# CC3220SF register map
Vendor: Texas Instruments; Series: Wireless Connectivity MCU; File version: 1
CPU: CM4 r1p0, little endian, no MPU, no FPU, 8 interrupt priority bits
Registers are 32-bit, read-write, reset 0x0 unless marked. A register's access mark holds for its fields unless they carry their own. Offsets are from the block's base; [hi:lo] are bit positions; {n}, {i} and the like mark numbered series.

## HIB3P3
Base 0x4402F800
0x00 MEM_HIB_REQ
  [8:2] NU1
0x04 MEM_HIB_RTC_TIMER_ENABLE
0x08 MEM_HIB_RTC_TIMER_RESET
0x0C MEM_HIB_RTC_TIMER_READ
0x10 MEM_HIB_RTC_TIMER_LSW
0x14 MEM_HIB_RTC_TIMER_MSW
  [15:0] HIB_RTC_TIMER_MSW — Upper 32b value of the latched RTC-Timer.
0x18 MEM_HIB_RTC_WAKE_EN
0x1C MEM_HIB_RTC_WAKE_LSW_CONF
0x20 MEM_HIB_RTC_WAKE_MSW_CONF
  [15:0] MEM_HIB_RTC_WAKE_MSW_CONF — Configuration for RTC-Timer Wakeup (Upper 16b word)
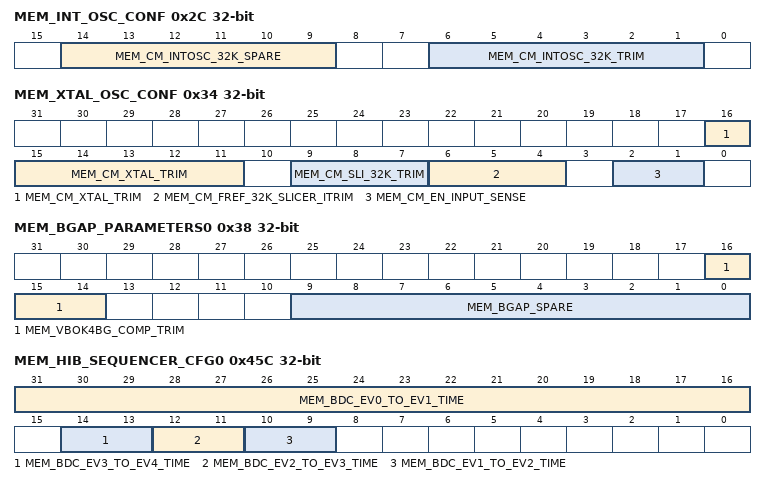
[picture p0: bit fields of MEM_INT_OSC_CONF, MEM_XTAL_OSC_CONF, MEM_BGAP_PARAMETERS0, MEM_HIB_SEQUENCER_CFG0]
0x2C MEM_INT_OSC_CONF
  [14:9] MEM_CM_INTOSC_32K_SPARE, [6:1] MEM_CM_INTOSC_32K_TRIM
0x34 MEM_XTAL_OSC_CONF
  [16:11] MEM_CM_XTAL_TRIM, [9:7] MEM_CM_SLI_32K_TRIM, [6:4] MEM_CM_FREF_32K_SLICER_ITRIM, [2:1] MEM_CM_EN_INPUT_SENSE
0x38 MEM_BGAP_PARAMETERS0
  [16:14] MEM_VBOK4BG_COMP_TRIM, [9:0] MEM_BGAP_SPARE
0x3C MEM_BGAP_PARAMETERS1
  [28:24] MEM_BGAP_ACT_IREF_ITRIM
0x40 MEM_HIB_DETECTION_STATUS
0x44 MEM_HIB_MISC_CONTROLS
  [8:6] MEM_HIB_POK_POR_COMP_TRIM
0x50 MEM_HIB_CONFIG
  [31:24] TOP_MUX_CTRL_SOP_SPIO
0x54 MEM_HIB_RTC_IRQ_ENABLE
0x58 MEM_HIB_RTC_IRQ_LSW_CONF
0x5C MEM_HIB_RTC_IRQ_MSW_CONF
  [15:0] HIB_RTC_IRQ_MSW_CONF — Configuration for MSW of thr RTC-Timestamp at which the interrupt need to be generated
0x400 MEM_HIB_UART_CONF
0x404 MEM_GPIO_WAKE_EN
  [7:0] MEM_GPIO_WAKE_EN — 1 - Enable the GPIO-Autonomous mode wakeup during Hibernate mode ; This is an auto-clear bit, once programmed to 1, it will latched into an internal register which remain asserted until the Hib-wakeup is initiated.
0x408 MEM_GPIO_WAKE_CONF
  [15:0] MEM_GPIO_WAKE_CONF — Configuration to say whether the GPIO wakeup has to happen on Level0 or falling-edge for the given group. 00? Level0 01? Level1 10?- Fall-edge 11?- Rise-edge [1:0] Conf for GPIO0 [3:2] Conf for GPIO1 [5:4] Conf for GPIO2 [7:6] Conf for GPIO3 [9:8] Conf for GPIO4 [11:10] Conf for GPIO5 [13:12] Conf for GPIO6
0x40C MEM_PAD_OEN_RET33_CONF
0x410 MEM_UART_RTS_OEN_RET33_CONF
0x414 MEM_JTAG_CONF
{0x418+4i} MEM_HIB_REG{i} (i=0..3)
0x45C MEM_HIB_SEQUENCER_CFG0
  [31:16] MEM_BDC_EV0_TO_EV1_TIME — Configuration for the number of slow-clks between de-assertion of EN_BG_3P3V to assertion of EN_BG_3P3V
  [14:13] MEM_BDC_EV3_TO_EV4_TIME — Configuration for the number of slow-clks between assertion of EN_COMP_3P3V and assertion of EN_COMP_LATCH_3P3V
  [12:11] MEM_BDC_EV2_TO_EV3_TIME — Configuration for the number of slow-clks between assertion of (EN_CAP_SW_3P3V,EN_COMP_REF) and assertion of (EN_COMP_3P3V)
  [10:9] MEM_BDC_EV1_TO_EV2_TIME — Configuration for the number of slow-clks between assertion of (EN_BG_3P3V) and assertion of (EN_CAP_SW_3P3V, EN_COMP_REF_3P3V)
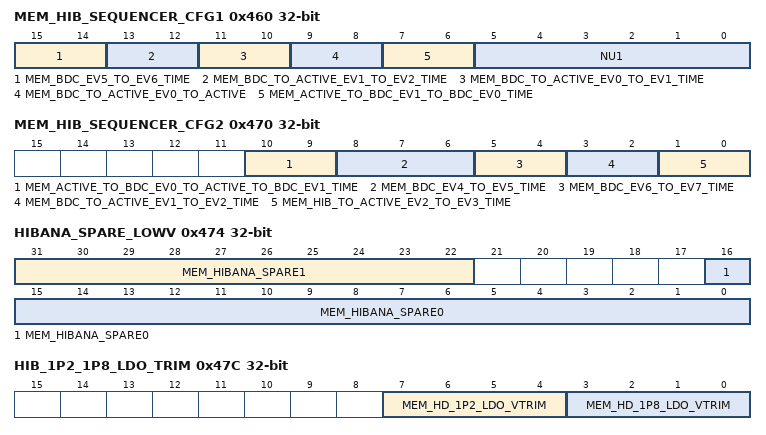
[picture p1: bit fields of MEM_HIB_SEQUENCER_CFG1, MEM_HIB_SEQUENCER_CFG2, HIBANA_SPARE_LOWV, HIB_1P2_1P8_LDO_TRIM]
0x460 MEM_HIB_SEQUENCER_CFG1
  [15:14] MEM_BDC_EV5_TO_EV6_TIME — Configuration for number of slow-clks between de-assertion of EN_COMP_LATCH and assertion of
  [13:12] MEM_BDC_TO_ACTIVE_EV1_TO_EV2_TIME — Configuration for number of slow-clks between assertion of EN_COMP_REF to assertion of EN_COMP during HIB-Exit
  [11:10] MEM_BDC_TO_ACTIVE_EV0_TO_EV1_TIME
  [9:8] MEM_BDC_TO_ACTIVE_EV0_TO_ACTIVE — Configuration in number of slow-clks between assertion of (EN_BGAP_3P3V, EN_CAP_SW_3P3V, EN_ACT_IREF_3P3V, EN_COMP_REF) to assertion of EN_COMP_3P3V
  [7:6] MEM_ACTIVE_TO_BDC_EV1_TO_BDC_EV0_TIME — Configuration in number of slow-clks between de-assertion of (EN_COMP_3P3V, EN_COMP_REF_3P3V, EN_ACT_IREF_3P3V, EN_CAP_SW_3P3V) to deassertion of EN_BGAP_3P3V.
  [5:0] NU1
0x464 MEM_HIB_MISC_CONFIG
0x468 MEM_HIB_WAKE_STATUS
  [4:1] HIB_WAKE_SRC — "0100" - GPIO ; "0010" - RTC ; "0001" - UART Others - Reserved
0x46C MEM_HIB_LPDS_GPIO_SEL
  [2:0] HIB_LPDS_GPIO_SEL
0x470 MEM_HIB_SEQUENCER_CFG2
  [10:9] MEM_ACTIVE_TO_BDC_EV0_TO_ACTIVE_TO_BDC_EV1_TIME — Deassertion of EN_COMP_LATCH_3P3 to deassertion of (EN_COMP_3P3, EN_COMP_REF_3P3, EN_ACT_IREF_3P3, EN_CAP_SW_3P3)
  [8:6] MEM_BDC_EV4_TO_EV5_TIME — Assertion of EN_COMP_LATCH_3P3 to deassertion of EN_COMP_LATCH_3P3
  [5:4] MEM_BDC_EV6_TO_EV7_TIME — Deassertion of (EN_CAP_SW_3P3, EN_COMP_REF_3P3, EN_COMP_3P3, EN_COMP_OUT_LATCH_3P3) to deassertion of EN_BGAP_3P3
  [3:2] MEM_BDC_TO_ACTIVE_EV1_TO_EV2_TIME — Assertion of EN_COMP_3P3 to assertion of EN_COMPOUT_LATCH_3P3
  [1:0] MEM_HIB_TO_ACTIVE_EV2_TO_EV3_TIME — Assertion of EN_COMP_3P3 to assertion of EN_COMPOUT_LATCH_3P3
0x474 HIBANA_SPARE_LOWV
  [31:22] MEM_HIBANA_SPARE1, [16:0] MEM_HIBANA_SPARE0
0x478 HIB_TMUX_CTRL
  [9:0] MEM_HD_TMUX_CNTRL
0x47C HIB_1P2_1P8_LDO_TRIM
  [7:4] MEM_HD_1P2_LDO_VTRIM, [3:0] MEM_HD_1P8_LDO_VTRIM
0x480 HIB_COMP_TRIM
  [2:0] MEM_HD_COMP_TRIM
0x484 HIB_EN_TS
0x488 HIB_1P8V_DET_EN
0x48C HIB_VBAT_MON_EN
0x490 HIB_NHIB_ENABLE
0x494 HIB_UART_RTS_SW_ENABLE
